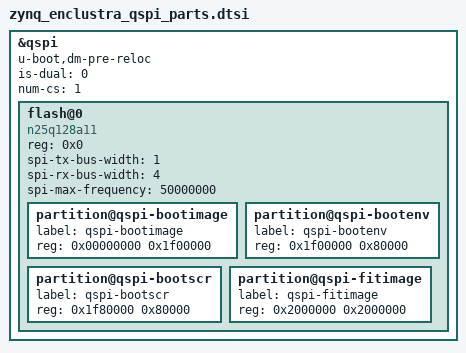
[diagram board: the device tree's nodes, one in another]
&qspi {
	u-boot,dm-pre-reloc;
	status = "okay";
	is-dual = <0>;
	num-cs = <1>;
	flash@0 {
		compatible = "n25q128a11";
		reg = <0x0>;
		spi-tx-bus-width = <1>;
		spi-rx-bus-width = <4>;
		spi-max-frequency = <50000000>;
		#address-cells = <1>;
		#size-cells = <1>;
		partition@qspi-bootimage {
			label = "qspi-bootimage";
			reg = <0x00000000 0x1f00000>;
		};
		partition@qspi-bootenv {
			label = "qspi-bootenv";
			reg = <0x1f00000 0x80000>;
		};
		partition@qspi-bootscr {
			label = "qspi-bootscr";
			reg = <0x1f80000 0x80000>;
		};
		partition@qspi-fitimage {
			label = "qspi-fitimage";
			reg = <0x2000000 0x2000000>;
		};
	};
};
